# DA1470x register map
Vendor: Dialog; Series: DA1470x; File version: 1.2
CPU: CM33 r0p2, little endian, MPU, FPU, DSP, VTOR, 4 interrupt priority bits
Registers are 32-bit, read-write, reset 0x0 unless marked. A register's access mark holds for its fields unless they carry their own. Offsets are from the block's base; [hi:lo] are bit positions.

## DCDC_BOOST — DCDC_BOOST registers
Base 0x50000500
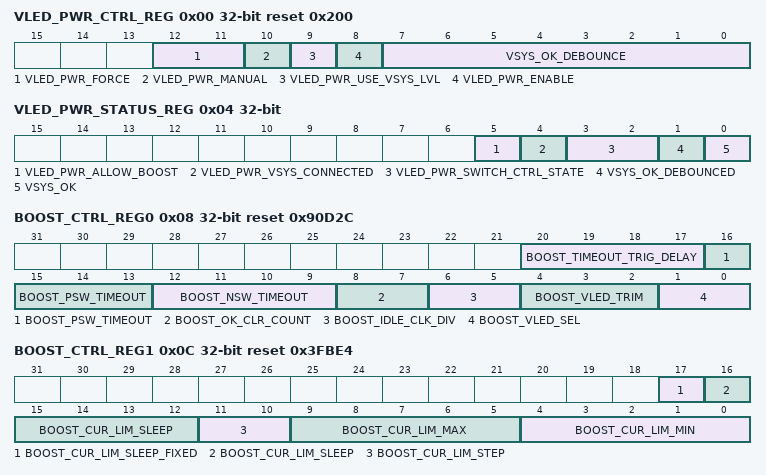
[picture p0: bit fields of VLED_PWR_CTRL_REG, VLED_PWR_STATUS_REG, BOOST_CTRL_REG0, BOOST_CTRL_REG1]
0x00 VLED_PWR_CTRL_REG reset 0x200
  [12:11] VLED_PWR_FORCE — Manual selection of VLED supply source, requires that VLED_PWR_MANUAL = 0x1 0x0: VLED not powered 0x1: VLED powered by VSYS 0x2: VLED powered by boost converter 0x3: N.A.
  [10] VLED_PWR_MANUAL — 0x0: VLED supply source automatically selected 0x1: VLED supply source manually selected
  [9] VLED_PWR_USE_VSYS_LVL — Sets the condition for powering VLED from VSYS 0x0: VLED always powered from VSYS 0x1: VLED powered form VSYS if VSYS is near VLED, depending on vsys-comparator (Default)
  [8] VLED_PWR_ENABLE — 0x0: VLED power controller disabled 0x1: VLED power controller enabled
  [7:0] VSYS_OK_DEBOUNCE — Sets debounce time on VSYS comparator in steps of 1.024 ms Note: actual delay can be up to one period of 1.024 ms clock shorter than programmed depending on alignment of comparator trip event and clock edge
0x04 VLED_PWR_STATUS_REG
  [5] VLED_PWR_ALLOW_BOOST ro — Indicates whether boost converter is blocked or not
  [4] VLED_PWR_VSYS_CONNECTED ro — Indicates that VSYS switch is closed
  [3:2] VLED_PWR_SWITCH_CTRL_STATE ro — State of the VLED power control FSM 0x0: Disabled 0x1: VSYS 0x2: Boost 0x3: N.A.
  [1] VSYS_OK_DEBOUNCED ro — Output of VSYS OK debounce logic
  [0] VSYS_OK ro — Output of VSYS OK logic
0x08 BOOST_CTRL_REG0 reset 0x90D2C
  [20:17] BOOST_TIMEOUT_TRIG_DELAY — Delay before generating next comparator clock after a timeout event on the P switch, allows inductor current to drop to zero 0x0: Disabled 0x1: 250 ns 0x2: 500 ns 0x3: 750 ns 0x4: 1000 ns (default) 0x5: 1250 ns 0x6: 1500 ns 0x7: 1750 ns 0x8: 2000 ns 0x9: 2250 ns 0xA: 2500 ns 0xB: 2750 ns 0xC: 3000 ns 0xD: 3250 ns 0xE: 3500 ns 0xF: 3750 ns
  [16:13] BOOST_PSW_TIMEOUT — P switch timeout, if switch is closed longer than this a timeout is generated and the FSM is forced to the next state 0x0: Disabled 0x1: 250 ns 0x2: 500 ns 0x3: 750 ns 0x4: 1000 ns 0x5: 1250 ns 0x6: 1500 ns 0x7: 1750 ns 0x8: 2000 ns (default) 0x9: 2250 ns 0xA: 2500 ns 0xB: 2750 ns 0xC: 3000 ns 0xD: 3250 ns 0xE: 3500 ns 0xF: 3750 ns
  [12:9] BOOST_NSW_TIMEOUT — N switch timeout, if switch is closed longer than this a timeout is generated and the FSM is forced to the next state 0x0: Disabled 0x1: 125 ns 0x2: 250 ns 0x3: 375 ns 0x4: 500 ns 0x5: 625 ns 0x6: 750 ns (default) 0x7: 875 ns 0x8: 1000 ns 0x9: 1125 ns 0xA: 1250 ns 0xB: 1375 ns 0xC: 1500 ns 0xD: 1625 ns 0xE: 1750 ns 0xF: 1875 ms
  [8:7] BOOST_OK_CLR_COUNT — Number of subsequent V_NOK events before BOOST_VLED_OK is reset 0x0: 2 0x1: 4 0x2: 8 (default) 0x3: 15
  [6:5] BOOST_IDLE_CLK_DIV — Determines times between comparator samples when converter is idle 0x0 = 250 ns 0x1 = 500 ns (default) 0x2 = 1000 ns 0x3 = 2000 ns
  [4:2] BOOST_VLED_TRIM — Trim setting for boost converter, sets deviation from nominal output voltage (4 V) 0x0: -75 mV 0x1: -50 mV 0x2: -25 mV 0x3: 0 mV (default) 0x4: 25 mV 0x5: 50 mV 0x6: 75 mV 0x7: 100 mV
  [1:0] BOOST_VLED_SEL — Voltage selection for boost converter, sets nominal output voltage 0x0: 4.50V (default) 0x1: 4.75V 0x2: 5.00V 0x3: 5.00V
0x0C BOOST_CTRL_REG1 reset 0x3FBE4
  [17] BOOST_CUR_LIM_SLEEP_FIXED — Enable fixed current iso dynamic current in sleep mode 0x0: Use dynamic current control 0x1: Use fixed current as defined in BOOST_CUR_LIM_SLEEP (default)
  [16:12] BOOST_CUR_LIM_SLEEP — Fixed inductor peak current limit in sleep mode I = 30 mA * (1 + N), default 960 mA
  [11:10] BOOST_CUR_LIM_STEP — Step size taken by automatic inductor peak current limit control 0x0: 0 (disabled) 0x1: 1 0x2: 2 (default) 0x3: 3
  [9:5] BOOST_CUR_LIM_MAX — Maximum inductor peak current limit I = 30 mA * (1 + N), default 960 mA
  [4:0] BOOST_CUR_LIM_MIN — Minimum inductor peak current limit I = 30 mA * (1 + N), default 150 mA
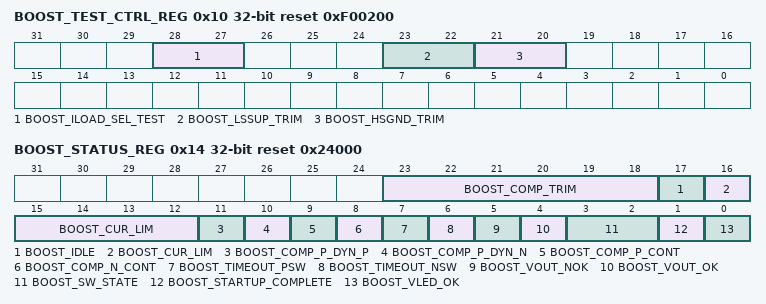
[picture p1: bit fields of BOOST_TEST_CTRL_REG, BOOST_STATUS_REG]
0x10 BOOST_TEST_CTRL_REG reset 0xF00200
  [28:27] BOOST_ILOAD_SEL_TEST — Test mode control for 20mA test-mux 0x0: All switches open (Default) 0x1: Sink 20mA from LX for testing PMOS 0x2: Sink 20mA from V_LED 0x3: Source 20mA into LX for testing NMOS
  [23:22] BOOST_LSSUP_TRIM — Trim low side supply voltage V = 2 V + 300 mV * N, default 2.9 V
  [21:20] BOOST_HSGND_TRIM — Trim high side ground V = VBAT - (2 V + 400 mV * N), default VBAT - 3.2 V
0x14 BOOST_STATUS_REG reset 0x24000
  [23:18] BOOST_COMP_TRIM ro — Actual P side comparator trim value
  [17] BOOST_IDLE ro — Converter idle
  [16:12] BOOST_CUR_LIM ro — Actual inductor peak current limit
  [11] BOOST_COMP_P_DYN_P ro — P output of P side dynamic comparator
  [10] BOOST_COMP_P_DYN_N ro — N output of P side dynamic comparator
  [9] BOOST_COMP_P_CONT ro — Output of P side continuous time comparator
  [8] BOOST_COMP_N_CONT ro — Output of N side continuous time comparator
  [7] BOOST_TIMEOUT_PSW ro — Timeout on P switch occurred
  [6] BOOST_TIMEOUT_NSW ro — Timeout on N switch occurred
  [5] BOOST_VOUT_NOK ro — NOK output of output voltage comparator
  [4] BOOST_VOUT_OK ro — OK output of output voltage comparator
  [3:2] BOOST_SW_STATE ro — State of boost converter switches 0x0: Both off 0x1: P switch on 0x2: N switch on 0x3: Undefined
  [1] BOOST_STARTUP_COMPLETE ro — Indicates if the converter is enabled and the startup counter has expired (internal biasing settled)
  [0] BOOST_VLED_OK ro — Indicates that V_LED is above its threshold, reset after too many subsequent V_NOK events
